# CAN_FD_IP_Core: IP-XACT component
VLNV CTU:ip:CAN_FD_IP_Core:2.1
CAN FD IP Core from Ondrej Ille written at Czech Technical University, department of Measurement.

## Parameters
sup_filt_A = 1
sup_range = 1
sup_filt_C = 1
sup_filt_B = 1
sup_traffic_ctrs = 1
txt_buffer_count = 4
sup_test_registers = 1

## Address spaces and blocks
CAN_Registers.Control_registers: base 'h0, range 256, width 32, register
CAN_Registers.TX_Buffer_1: base 'h100, range 256, width 32, memory
CAN_Registers.TX_Buffer_2: base 'h200, range 256, width 32, memory
CAN_Registers.TX_Buffer_3: base 'h300, range 256, width 32, memory
CAN_Registers.TX_Buffer_4: base 'h400, range 256, width 32, memory
CAN_Registers.TX_Buffer_5: base 'h500, range 256, width 32, memory
CAN_Registers.TX_Buffer_6: base 'h600, range 256, width 32, memory
CAN_Registers.TX_Buffer_7: base 'h700, range 256, width 32, memory
CAN_Registers.TX_Buffer_8: base 'h800, range 256, width 32, memory
CAN_Registers.Test_registers: base 'h900, range 256, width 32, register
CAN_Frame_format.CAN_FD_Frame_format: base 'h0, range 84, width 32

## Registers
Registers are 32-bit, access not given, no defined reset value unless marked. A register's access mark holds for its fields unless they carry their own. Offsets are from the block's base; lines under a group give offsets from that group; [hi:lo] are bit positions; {n}, {i} and the like mark numbered series; 'fields as' and 'values as' point back to an identical list; <NAME> marks a mode.

## CAN_Registers.Control_registers — Control registers memory region.
Base 0x00000000
0x00 DEVICE_ID 16-bit ro reset 0xCAFD — Identifer of CTU CAN FD. Can be used to check if CTU CAN FD is accessible correctly on its base address.
  [15:0] DEVICE_ID
    0xCAFD=CTU_CAN_FD_ID (Identifier of CTU CAN FD.)
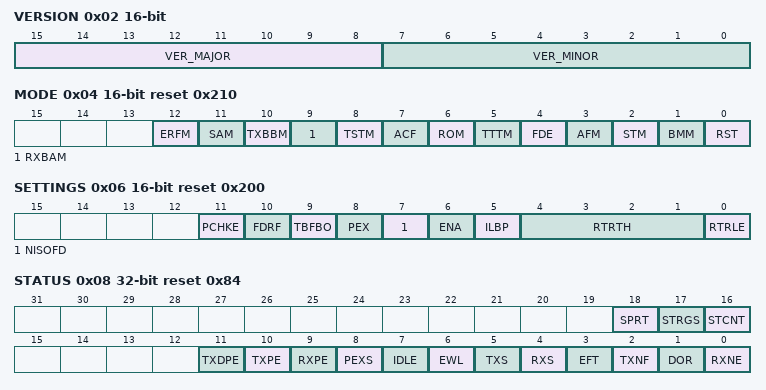
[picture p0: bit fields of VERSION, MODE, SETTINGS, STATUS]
0x02 VERSION 16-bit ro — Version register. Returns version of CTU CAN FD.
  [15:8] VER_MAJOR — Minor part of CTU CAN FD version. E.g for version 2.1 this field has value 0x02.
  [7:0] VER_MINOR — Minor part of CTU CAN FD version. E.g for version 2.1 this field has value 0x01.
0x04 MODE 16-bit rw reset 0x210 (reset mask 0xFFF)
  [12] ERFM — Error Frame Receive mode. When set, CTU CAN FD receives Error frames on CAN bus into its RX buffer.
    1=ERFM_ENABLED (Error frames are stored to RX buffer.); 0=ERFM_DISABLED (Error frames are not stored to RX Buffer.)
  [11] SAM — Self-acknowledge mode.
    0=SAM_DISABLE (Do not send dominant ACK bit when CTU CAN FD sends Acknowledge bit.); 1=SAM_ENABLE (Send dominant ACK bit when CTU CAN FD transmits CAN frame.)
  [10] TXBBM — TXT Buffer Backup mode.
    0=TXBBM_DISABLED (TXT Buffer Backup mode disabled.); 1=TXBBM_ENABLED (TXT Buffer Backup mode enabled.)
  [9] RXBAM — RX Buffer Automatic mode.
    0=RXBAM_DISABLED (RX Buffer Automatic mode Disabled.); 1=RXBAM_ENABLED (RX Buffer Automatic mode Enabled.)
  [8] TSTM — Test Mode. In test mode several registers have special features. Reffer to description of Test mode for further details.
  [7] ACF — Acknowledge Forbidden Mode. When enabled, acknowledge is not sent even if received CRC matches the calculated one.
    1=ACF_ENABLED (Acknowledge forbidden mode enabled.); 0=ACF_DISABLED (Acknowledge forbidden mode disabled.)
  [6] ROM — Restricted operation mode.
    1=ROM_ENABLED (Restricted operation mode is enabled.); 0=ROM_DISABLED (Restricted operation mode is disabled.)
  [5] TTTM — Time triggered transmission mode.
    1=TTTM_ENABLED (Time Triggerer transmission is enabled. A frame from highest priority TXT Buffer in Ready state is admitted for transmission when its timestamp lower than CTU CAN FD timebase.); 0=TTTM_DISABLED (Time Triggerer transmission is disabled. A frame from highest priority TXT Buffer in Ready state is admitted for transmission regardless of its timestamp.)
  [4] FDE — Flexible data rate enable. When flexible data rate is enabled CTU CAN FD recognizes CAN FD frames (FDF bit = 1).
    1=FDE_ENABLE (Flexible data-rate support enabled.); 0=FDE_DISABLE (Flexible data-rate support disabled.)
  [3] AFM — Acceptance Filters Mode. If enabled, only RX frames which pass Frame filters are stored in RX buffer. If disabled, every received frame is stored to RX buffer. This bit has meaning only if there is at least one filter available. Otherwise, this bit is reserved.
    1=AFM_ENABLED (Acceptance filter mode enabled); 0=AFM_DISABLED (Acceptance filter mode disabled)
  [2] STM — Self Test Mode. In this mode transmitted frame is considered valid even if dominant acknowledge was not received.
    1=STM_ENABLED (Self test mode enabled.); 0=STM_DISABLED (Self test mode disabled.)
  [1] BMM — Bus monitoring mode. In this mode CTU CAN FD only receives frames and sends only recessive bits on CAN bus. When a dominant bit is sent, it is re-routed internally so that bus value is not changed. When this mode is enabled, CTU CAN FD will not transmit any frame from TXT Buffers,
    1=BMM_ENABLED (Bus monitoring mode enabled.); 0=BMM_DISABLED (Bus monitoring mode disabled.)
  [0] RST write-clears — Soft reset. Writing logic 1 resets CTU CAN FD. After writing logic 1, logic 0 does not need to be written, this bit is automatically cleared.
0x06 SETTINGS 16-bit rw reset 0x200 (reset mask 0x7FF)
  [11] PCHKE — Enable Parity checks in TXT Buffers and RX Buffer.
  [10] FDRF — Frame filters drop Remote frames.
    1=DROP_RF_ENABLED (Frame filters drop RTR frames.); 0=DROP_RF_DISABLED (Frame filters accept RTR frames.)
  [9] TBFBO — All TXT buffers shall go to "TX failed" state when CTU CAN FD becomes bus-off.
    1=TXTBUF_FAILED_BUS_OFF_ENABLED (TXT Buffers go to "TX failed" state when CTU CAN FD becomes bus-off.); 0=TXTBUF_FAILED_BUS_OFF_DISABLED (TXT Buffers dont go to "TX failed" state when CTU CAN FD becomes bus-off.)
  [8] PEX — Protocol exception handling. When this bit is set, CTU CAN FD will start integration upon detection of protocol exception. This should be modified only when SETTINGS[ENA] = '0'.
    0=PROTOCOL_EXCEPTION_DISABLED (Protocol exception handling is disabled.); 1=PROTOCOL_EXCEPTION_ENABLED (Protocol exception handling is enabled.)
  [7] NISOFD — Non ISO FD. When this bit is set, CTU CAN FD is compliant to NON-ISO CAN FD specification (no stuff count field). This bit should be modified only when SETTINGS[ENA]=0.
    0=ISO_FD (The CAN Controller conforms to ISO CAN FD specification.); 1=NON_ISO_FD (The CAN Controller conforms to NON ISO CAN FD specification.)
  [6] ENA — Main enable bit of CTU CAN FD. When enabled, CTU CAN FD communicates on CAN bus. When disabled, it is bus-off and does not take part of CAN bus communication.
    1=CTU_CAN_ENABLED (The CAN Core is enabled.); 0=CTU_CAN_DISABLED (The CAN Core is disabled.)
  [5] ILBP — Internal Loop Back mode. When enabled, CTU CAN FD receives any frame it transmitts.
    0=INT_LOOP_DISABLED (Internal loop-back is disabled.); 1=INT_LOOP_ENABLED (Internal loop-back is enabled.)
  [4:1] RTRTH — Retransmitt Limit Threshold. Maximal amount of retransmission attempts when SETTINGS[RTRLE] is enabled.
  [0] RTRLE — Retransmitt Limit Enable. If enabled, CTU CAN FD only attempts to retransmitt each frame up to RTR_TH times.
    1=RTRLE_ENABLED (Retransmitt limit is enabled.); 0=RTRLE_DISABLED (Retransmitt limit is disabled.)
0x08 STATUS ro reset 0x84 (reset mask 0xFFF)
  [18] SPRT — Support of Parity protection on each word of TXT Buffer RAM and RX Buffer RAM.
  [17] STRGS — Support of Test Registers for memory testability. When this bit is 1, Test Registers are present.
  [16] STCNT — Support of Traffic counters. When this bit is 1, Traffic counters are present.
  [11] TXDPE — TXT Buffer double parity error. Set in TXT Buffer Backup mode when parity error is detected in "backup" TXT Buffer.
  [10] TXPE — TXT Buffers Parity Error flag. Set When Parity Error is detected in a TXT Buffer during transmission from this buffer.
  [9] RXPE — Set when parity error is detected during read of CAN frame from RX Buffer via RX_DATA register.
  [8] PEXS — Protocol exception status (flag). Set when Protocol exception occurs. Cleared by writing COMMAND[CPEXS]=1.
  [7] IDLE — Bus is idle (no frame is being transmitted/received) or CTU CAN FD is bus-off.
  [6] EWL — TX Error counter (TEC) or RX Error counter (REC) is equal to, or higher than Error warning limit (EWL).
  [5] TXS — CTU CAN FD is transmitter of CAN Frame.
  [4] RXS — CTU CAN FD is receiver of CAN Frame.
  [3] EFT — Error frame is being transmitted at the moment.
  [2] TXNF — TXT buffers status. This bit is set if at least one TXT buffer is in "Empty" state.
  [1] DOR — Data Overrun flag. This bit is set when frame was dropped due to lack of space in RX buffer. This bit can be cleared by COMMAND[RRB] or COMMAND[CDO].
  [0] RXNE — RX buffer not empty. This bit is 1 when least one frame is stored in RX buffer.
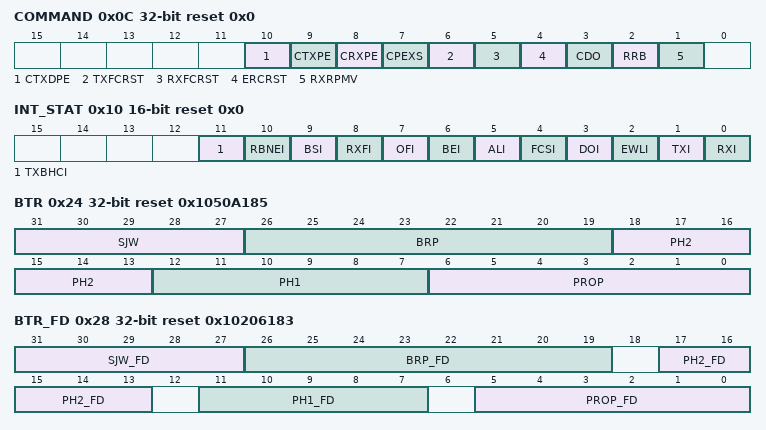
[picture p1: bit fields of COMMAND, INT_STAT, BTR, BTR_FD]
0x0C COMMAND wo reset 0x0 (reset mask 0x7FC) — Allows issuing commands to CTU CAN FD. Writing logic 1 to each bit gives a command to CTU CAN FD. After writing logic 1, logic 0 does not need to be written.
  [10] CTXDPE write-clears — Clear STATUS[TXDPE] flag.
  [9] CTXPE write-clears — Clear STATUS[TXPE] flag.
  [8] CRXPE write-clears — Clear STATUS[RXPE] flag.
  [7] CPEXS write-clears — Clear Protocol exception status (STATUS[PEXS]).
  [6] TXFCRST write-clears — Clear TX bus traffic counter (TX_COUNTER register).
  [5] RXFCRST write-clears — Clear RX bus traffic counter (RX_COUNTER register).
  [4] ERCRST write-clears — Error Counters Reset. When unit is bus off, issuing this command will request erasing TEC, REC counters after 128 consecutive ocurrences of 11 recessive bits. Upon completion, TEC and REC are erased and fault confinement state is set to error-active. When unit is not bus-off, or when unit is bus-off due to being disabled (SETTINGS[ENA] = '0'), this command has no effect.
  [3] CDO write-clears — Clear Data Overrun flag in RX buffer.
  [2] RRB write-clears — Release RX Buffer. This command flushes RX buffer and resets its memory pointers.
  [1] RXRPMV write-clears — RX Buffer read pointer move.
0x10 INT_STAT 16-bit rw-once reset 0x0 — Interrupt Status register. Reading this register returns logic 1 for each interrupt which ocurred. Writing logic 1 to any bit clears according interrupt status. Writing logic 0 has no effect.
  [11] TXBHCI write-clears — TXT buffer HW command interrupt. Anytime TXT buffer receives HW command from CAN Core which changes TXT buffer state to "TX OK", "Error" or "Aborted", this interrupt will be generated.
  [10] RBNEI write-clears — RX buffer not empty interrupt. Clearing this interrupt and not reading out content of RX Buffer via RX_DATA will re-activate the interrupt.
  [9] BSI write-clears — Bit rate shifted interrupt.
  [8] RXFI write-clears — RX buffer full interrupt.
  [7] OFI write-clears — Overload frame interrupt.
  [6] BEI write-clears — Bus error interrupt.
  [5] ALI write-clears — Arbitration lost interrupt.
  [4] FCSI write-clears — Fault confinement state changed interrupt. Interrupt is set when node turns error-passive (from error-active), bus-off (from error-passive) or error-active (from bus-off after reintegration or from error-passive).
  [3] DOI write-clears — Data overrun interrupt. Before this interrupt is cleared , STATUS[DOR] must be cleared to avoid setting of this interrupt again.
  [2] EWLI write-clears — Error warning limit interrupt. When both TEC and REC are lower than EWL and one of the becomes equal to or higher than EWL, or when both TEC and REC become less than EWL, this interrupt is generated. When Interrupt is cleared and REC, or TEC is still equal to or higher than EWL, Interrupt is not generated again.
  [1] TXI write-clears — Frame transmitted interrupt.
  [0] RXI write-clears — Frame received interrupt.
0x14 INT_ENA_SET 16-bit rw-once reset 0x0 — Interrupt Enable Set. Writing logic 1 to a bit enables according interrupt. Writing logic 0 has no effect. Reading this register returns logic 1 for each enabled interrupt. If interrupt is captured in INT_STAT, enabled interrupt will cause CTU CAN FD to raise interrupt. Interrupts are level-based, it remains active until Interrupt status is cleared or interrupt is disabled.
  [11:0] INT_ENA_SET write-clears — Bit meaning is equivalent to register INT_STAT.
0x18 INT_ENA_CLR 16-bit wo reset 0x0 — Interrupt Enable Clear register. Writing logic 1 disables according interrupt. Writing logic 0 has no effect. Reading this register has no effect. Disabled interrupt wil not cause interrupt to be raised by CTU CAN FD even if it is set in Interrupt status register.
  [11:0] INT_ENA_CLR write-clears — Bit meaning is equivalent to register INT_STAT.
0x1C INT_MASK_SET 16-bit rw-once reset 0x0 — Interrupt Mask set. Writing logic 1 masks according interrupt. Writing logic 0 has no effect. Reading this register returns logic 1 for each masked interrupt. If particular interrupt is masked, it won't be captured in INT_STAT register when internal conditions for this interrupt are met (e.g RX buffer is not empty for RXNEI).
  [11:0] INT_MASK_SET write-clears — Bit meaning is equivalent to register INT_STAT.
0x20 INT_MASK_CLR 16-bit wo reset 0x0 — Interrupt Mask clear register. Writing logic 1 un-masks according interrupt. Writing logic 0 has no effect. Reading this register has no effect. If particular interrupt is un-masked, it will be captured in INT_STAT register when internal conditions for this interrupt are met (e.g RX buffer is not empty for RXNEI).
  [11:0] INT_MASK_CLR write-clears — Bit meaning is equivalent to register INT_STAT.
0x24 BTR rw reset 0x1050A185 — Bit timing register for nominal bit rate.
  [31:27] SJW — Synchronisation jump width
  [26:19] BRP — Bit rate prescaler
  [18:13] PH2 — Phase 2 segment
  [12:7] PH1 — Phase 1 segment
  [6:0] PROP — Propagation segment
0x28 BTR_FD rw reset 0x10206183 — Bit timing register for data bit rate.
  [31:27] SJW_FD — Synchronisation jump width
  [26:19] BRP_FD — Bit rate prescaler
  [17:13] PH2_FD — Phase 2 segment
  [11:7] PH1_FD — Phase 1 segment
  [5:0] PROP_FD — Propagation segment
0x2C EWL 8-bit rw reset 0x60 — Error warning limit register. This register shall be modified only when SETTINGS[ENA]=0.
  [7:0] EW_LIMIT — Error warning limit. If error warning limit is reached interrupt can be generated. Error warning limit indicates heavily disturbed bus.
0x2D ERP 8-bit rw reset 0x80 — Error passive limit register. This register shall be modified only when SETTINGS[ENA]=0.
  [7:0] ERP_LIMIT — Error Passive Limit. When one of error counters (REC/TEC) exceeds this value, Fault confinement state changes to error-passive.
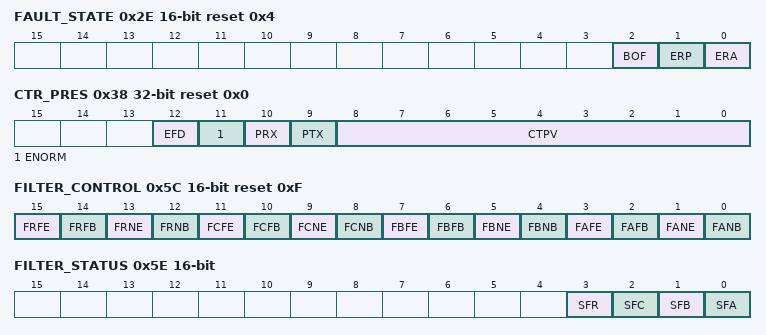
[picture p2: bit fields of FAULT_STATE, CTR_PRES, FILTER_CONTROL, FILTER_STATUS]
0x2E FAULT_STATE 16-bit ro reset 0x4 — Fault Confinement state of the CTU CAN FD.
  [2] BOF — Bus-off
  [1] ERP — Error-passive
  [0] ERA — Error-active
0x30 REC 16-bit ro reset 0x0
  [8:0] REC_VAL — RX error counter (REC).
0x32 TEC 16-bit ro reset 0x0
  [8:0] TEC_VAL — TX error counter (TEC).
0x34 ERR_NORM 16-bit ro reset 0x0
  [15:0] ERR_NORM_VAL — Number of errors which occured in nominal bit rate.
0x36 ERR_FD 16-bit ro reset 0x0
  [15:0] ERR_FD_VAL — Number of errors which occured in data bit rate.
0x38 CTR_PRES wo reset 0x0 — Counter preset register. Error counters can be modified via this register.
  [12] EFD write-clears — Erase Data bit rate error counter (ERR_FD).
  [11] ENORM write-clears — Erase Nominal bit rate error counter (ERR_NORM).
  [10] PRX write-clears — Preset value from CTPV to RX Error counter (REC).
  [9] PTX write-clears — Preset value from CTPV to TX Error counter (TEC).
  [8:0] CTPV — Counter value to set.
0x3C FILTER_A_MASK rw reset 0x0
  [28:0] BIT_MASK_A_VAL — Filter A mask. The identifier format is the same as in IDENTIFIER_W of TXT buffer or RX buffer. If filter A is not present, writes to this register have no effect and read will return all zeroes.
0x40 FILTER_A_VAL rw reset 0x0
  [28:0] BIT_VAL_A_VAL — Filter A value. The identifier format is the same as in IDENTIFIER_W of TXT buffer or RX buffer. If filter A is not present, writes to this register have no effect and read will return all zeroes.
0x44 FILTER_B_MASK rw reset 0x0
  [28:0] BIT_MASK_B_VAL — Filter B mask. The identifier format is the same as in IDENTIFIER_W of TXT buffer or RX buffer. If filter A is not present, writes to this register have no effect and read will return all zeroes.
0x48 FILTER_B_VAL rw reset 0x0
  [28:0] BIT_VAL_B_VAL — Filter B value. The identifier format is the same as in IDENTIFIER_W of TXT buffer or RX buffer. If filter A is not present, writes to this register have no effect and read will return all zeroes.
0x4C FILTER_C_MASK rw reset 0x0
  [28:0] BIT_MASK_C_VAL — Filter C mask. The identifier format is the same as in IDENTIFIER_W of TXT buffer or RX buffer. If filter A is not present, writes to this register have no effect and read will return all zeroes.
0x50 FILTER_C_VAL rw reset 0x0
  [28:0] BIT_VAL_C_VAL — Filter C value. The identifier format is the same as in IDENTIFIER_W of TXT buffer or RX buffer. If filter A is not present, writes to this register have no effect and read will return all zeroes.
0x54 FILTER_RAN_LOW rw reset 0x0
  [28:0] BIT_RAN_LOW_VAL — Filter Range Low threshold. The identifier format is the same as in IDENTIFIER_W of TXT buffer or RX buffer. If Range filter is not supported, writes to this register have no effect and read will return all zeroes.
0x58 FILTER_RAN_HIGH rw reset 0x0
  [28:0] BIT_RAN_HIGH_VAL — Range filter High threshold. The identifier format is the same as in IDENTIFIER_W of TXT buffer or RX buffer. If Range filter is not supported, writes to this register have no effect and read will return all zeroes.
0x5C FILTER_CONTROL 16-bit rw reset 0xF — Filter control register. Configures Frame filters to accept only selected frame types. Every bit is active in logic 1.
  [15] FRFE — CAN FD Extended Frame is accepted by Range filter.
  [14] FRFB — CAN FD Basic Frame is accepted by Range filter.
  [13] FRNE — CAN Extended Frame is accepted by Range filter.
  [12] FRNB — CAN Basic Frame is accepted by Range filter.
  [11] FCFE — CAN FD Extended Frame is accepted by filter C.
  [10] FCFB — CAN FD Basic Frame is accepted by filter C.
  [9] FCNE — CAN Extended Frame is accepted by Filter C.
  [8] FCNB — CAN Basic Frame is accepted by filter C.
  [7] FBFE — CAN FD Extended Frame is accepted by filter B.
  [6] FBFB — CAN FD Basic Frame is accepted by filter B.
  [5] FBNE — CAN Extended Frame is accepted by Filter B.
  [4] FBNB — CAN Basic Frame is accepted by filter B.
  [3] FAFE — CAN FD Extended Frame is accepted by filter A.
  [2] FAFB — CAN FD Basic Frame is accepted by filter A.
  [1] FANE — CAN Extended Frame is accepted by Filter A.
  [0] FANB — CAN Basic Frame is accepted by filter A.
0x5E FILTER_STATUS 16-bit ro — Filter status indicates if frame filters are available in CTU CAN FD.
  [3] SFR — Logic 1 when Range Filter is available. Otherwise logic 0.
  [2] SFC — Logic 1 when Filter C is available. Otherwise logic 0.
  [1] SFB — Logic 1 when Filter B is available. Otherwise logic 0.
  [0] SFA — Logic 1 when Filter A is available. Otherwise logic 0.
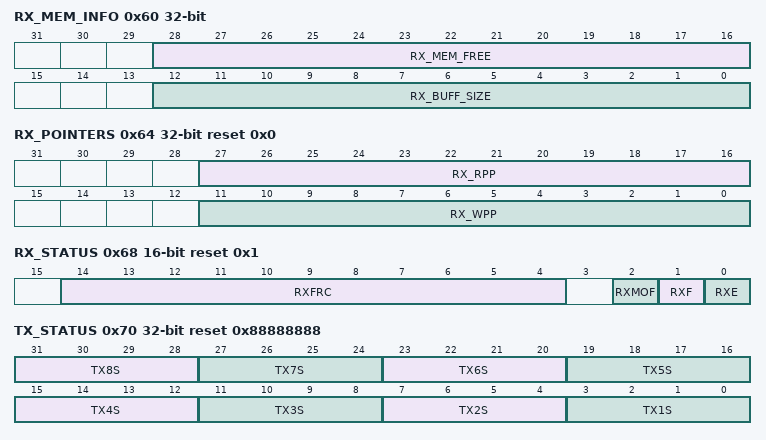
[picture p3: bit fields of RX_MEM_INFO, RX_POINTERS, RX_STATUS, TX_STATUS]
0x60 RX_MEM_INFO ro
  [28:16] RX_MEM_FREE — Number of free 32 bit words in RX buffer.
  [12:0] RX_BUFF_SIZE — Size of RX buffer in 32-bit words.
0x64 RX_POINTERS ro reset 0x0
  [27:16] RX_RPP — Read pointer position in RX buffer. Upon read of received frame read pointer is updated.
  [11:0] RX_WPP — Write pointer position in RX buffer. Upon store of received frame write pointer is updated.
0x68 RX_STATUS 16-bit ro reset 0x1
  [14:4] RXFRC — RX buffer frame count. Number of CAN frames stored in RX buffer.
  [2] RXMOF — RX Buffer middle of frame. When RXMOF = 1, next read from RX_DATA register will return other than first word (FRAME_FORMAT_W) of CAN frame.
  [1] RXF — RX buffer is full, all memory words of RX buffer are occupied.
  [0] RXE — RX buffer is empty. There is no CAN Frame stored in it.
0x6A RX_SETTINGS 8-bit rw reset 0x0 — Settings of RX buffer FIFO.
  [0] RTSOP — Receive buffer timestamp option. This register should be modified only when SETTINGS[ENA]=0.
    0=RTS_END (Timestamp of received frame in RX FIFO is captured in last bit of EOF field.); 1=RTS_BEG (Timestamp of received frame in RX FIFO is captured in SOF field.)
0x6C RX_DATA ro reset 0x0
  [31:0] RX_DATA read-modifies — RX buffer data at read pointer position in FIFO. By reading from this register, read pointer is automatically incremented if MODES[RXBAM]=1 and RX Buffer is not empty. If MODE[RXBAM]=1, this register must be read by 32 bit access. Upon read from this register, STATUS[RXPE] is set if there is parity error detected in RX Buffer word which is being read.
0x70 TX_STATUS ro reset 0x88888888
  [4n-1:4n-4] TX{n}S (n=2..8) — Status of TXT buffer {n}. Bit field meaning is analogous to TX1S.
  [3:0] TX1S — Status of TXT buffer 1.
    8=TXT_ETY (TXT buffer is in "Empty" state.); 4=TXT_TOK (TXT buffer is in "TX OK" state.); 6=TXT_ERR (TXT buffer is in "Failed" state.); 0=TXT_NOT_EXIST (TXT buffer does not exist in the core (applies only to TXT buffers 3-8, when CTU CAN FD was synthesized with less than 8 TXT buffers).); 9=TXT_PER (TXT Buffer is in "Parity Error" state. CTU CAN FD detected parity error on this buffer.); 7=TXT_ABT (TXT buffer is in "Aborted" state.); 2=TXT_TRAN (TXT buffer is in "TX in progress" state. CTU CAN FD is transmitting frame.); 3=TXT_ABTP (TXT buffer is in "Abort in progress" state.); 1=TXT_RDY (TXT buffer is in "Ready" state, it is waiting for CTU CAN FD to start transmission from it.)
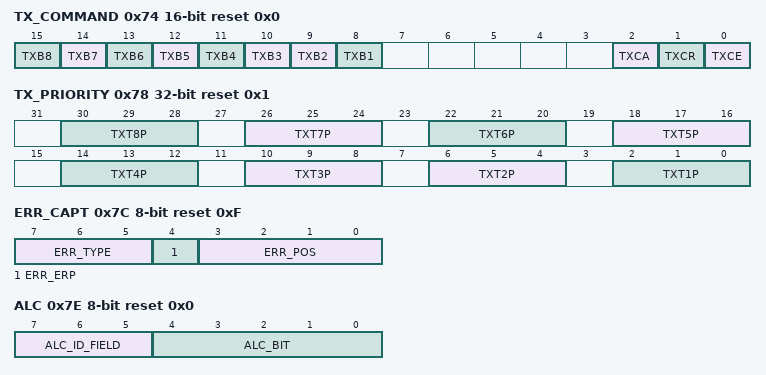
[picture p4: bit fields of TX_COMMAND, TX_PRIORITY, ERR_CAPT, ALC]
0x74 TX_COMMAND 16-bit wo reset 0x0 — Command register for TXT buffers. Command is activated by writing logic 1 to TXC(E|R|A) bit. TXT buffer that receives the command is selected by setting bit TXB[1-8] to logic 1. Command and index can be set by single access, or index can be set in advance. TXC(E|R|A) bits are automatically erased upon the command completion. Reffer to description of TXT buffer for meaning of commands. If TXCE and TXCR are applied simultaneously, only TXCE command is applied. If multiple commands are applied at once, only those which have effect in immediate state of TXT buffer are applied to the buffer.
  [n+7] TXB{n} (n=3..8) — Command is issued to TXT Buffer {n}. If number of TXT Buffers is less than {n}, this field is reserved and has no function.
  [9] TXB2 — Command is issued to TXT Buffer 2.
  [8] TXB1 — Command is issued to TXT Buffer 1.
  [2] TXCA write-clears — Issues "set abort" command.
  [1] TXCR write-clears — Issues "set ready" command.
  [0] TXCE write-clears — Issues "set empty" command.
0x76 TXTB_INFO 16-bit ro — Register with information about supported features of TXT buffers.
  [3:0] TXT_BUFFER_COUNT — Number of TXT buffers present in CTU CAN FD. Lowest buffer is always 1. Highest buffer is at index equal to number of present buffers.
0x78 TX_PRIORITY rw reset 0x1 — Priority of TXT buffers. Highest priority TXT buffer in "Ready" state is selected for transmission.
  [4n-2:4n-4] TXT{n}P (n=3..8) — Priority of TXT buffer {n}. If number of TXT Buffers is less than {n}, this field is reserved and has no function.
  [6:4] TXT2P — Priority of TXT buffer 2.
  [2:0] TXT1P — Priority of TXT buffer 1.
0x7C ERR_CAPT 8-bit ro reset 0xF — Error code capture register. Determines position within CAN frame where last error was detected.
  [7:5] ERR_TYPE — Type of last error.
    0=ERC_BIT_ERR (Bit Error); 1=ERC_CRC_ERR (CRC Error); 2=ERC_FRM_ERR (Form Error); 3=ERC_ACK_ERR (Acknowledge Error); 4=ERC_STUF_ERR (Stuff Error); 5=ERC_PRT_ERR (Parity Error in TXT Buffer RAM DATA_1_4_W ... DATA_61_64_W words.)
  [4] ERR_ERP — CTU CAN FD was error passive the time when last error was detected.
    1=ERR_ERP_PASSIVE (CTU CAN FD was error active when it detected the error condition.); 0=ERR_ERP_ACTIVE (CTU CAN FD was error passive when it detected the error condition.)
  [3:0] ERR_POS — Position of last error.
    0=ERC_POS_SOF (Error in Start of Frame); 1=ERC_POS_ARB (Error in Arbitration Filed); 7=ERC_POS_ERR (Error during Error frame); 8=ERC_POS_OVRL (Error in Overload frame); 2=ERC_POS_CTRL (Error in Control field); 15=ERC_POS_OTHER (Other position of error); 3=ERC_POS_DATA (Error in Data Field); 4=ERC_POS_CRC (Error in CRC Field); 6=ERC_POS_EOF (Error in End of frame field); 5=ERC_POS_ACK (Error in CRC delimiter, ACK field or ACK delimiter)
0x7D RETR_CTR 8-bit ro reset 0x0 — Current value of Retransmit counter.
  [3:0] RETR_CTR_VAL — Current value of retransmitt counter.
0x7E ALC 8-bit ro reset 0x0 — Arbitration lost capture register. Determines position of last arbitration loss within CAN frame.
  [7:5] ALC_ID_FIELD — Part of CAN Identifier in which arbitration was lost.
    1=ALC_BASE_ID (Arbitration was lost during base identifier.); 2=ALC_SRR_RTR (Arbitration was lost during first bit after base identifier (SRR of Extended Frame, RTR bit of CAN 2.0 Base Frame)); 3=ALC_IDE (Arbitration was lost during IDE bit.); 4=ALC_EXTENSION (Arbitration was lost during Identifier extension.); 5=ALC_RTR (Arbitration was lost during RTR bit after Identifier extension!); 0=ALC_RSVD (Unit did not loose arbitration since last reset.)
  [4:0] ALC_BIT — Arbitration lost capture bit position. If ALC_ID_FIELD = ALC_BASE_ID then bit index of BASE identifier in which arbitration was lost is given as: 11 - ALC_VAL. If ALC_ID_FIELD = ALC_EXTENSION then bit index of EXTENDED identifier in which arbitration was lost is given as: 18 - ALC_VAL. For other values of ALC_ID_FIELD, this value is undefined.
0x7F TS_INFO 8-bit ro — Timestamp integration information
  [5:0] TS_BITS — Number of active bits of CTU CAN FD time-base minus 1 (0x3F = 64 bit time-base).
0x80 TRV_DELAY 16-bit ro reset 0x0 — Transmitter delay register. When transmitting CAN FD Frame, Transmitter delay is measured. After the measurement (after FDF bit), it can be read out from this register. The value in this register is valid since first transmission of CAN FD frame. After each next measurement the value is updated.
  [7:0] TRV_DELAY_VALUE — Measured Transmitter delay in multiple of minimal Time quanta.
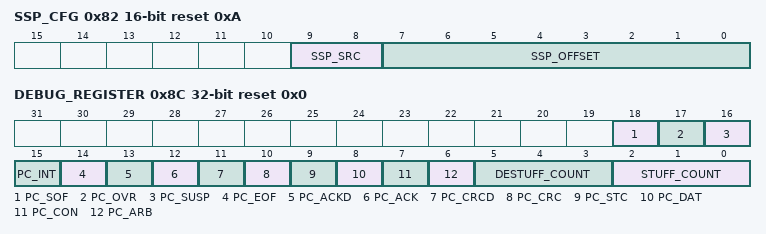
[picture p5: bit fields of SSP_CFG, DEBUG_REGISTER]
0x82 SSP_CFG 16-bit rw reset 0xA — Secondary sampling point configuration register. Used by transmitter in data bit rate for calculation of Secondary sampling point.
  [9:8] SSP_SRC — Source of Secondary sampling point.
    2=SSP_SRC_OFFSET (SSP position = SSP_OFFSET. Measured Transmitter delay value is ignored.); 0=SSP_SRC_MEAS_N_OFFSET (SSP position = TRV_DELAY (Measured Transmitter delay) + SSP_OFFSET.); 1=SSP_SRC_NO_SSP (SSP is not used. Transmitter uses regular Sampling Point during data bit rate.)
  [7:0] SSP_OFFSET — Secondary sampling point offset. Value is given as multiple of minimal Time quanta.
0x84 RX_FR_CTR ro reset 0x0
  [31:0] RX_FR_CTR_VAL — Number of received frames by CTU CAN FD.
0x88 TX_FR_CTR ro reset 0x0
  [31:0] TX_FR_CTR_VAL — Number of transmitted frames by CTU CAN FD.
0x8C DEBUG_REGISTER ro reset 0x0 — Register for reading state of the controller. This register is only for debugging purposes!
  [18] PC_SOF — Protocol control state machine is in Start of frame field.
  [17] PC_OVR — Protocol control state machine is in Overload field.
  [16] PC_SUSP — Protocol control state machine is in Suspend transmission field.
  [15] PC_INT — Protocol control state machine is in Intermission field.
  [14] PC_EOF — Protocol control state machine is in End of file field.
  [13] PC_ACKD — Protocol control state machine is in ACK Delimiter field.
  [12] PC_ACK — Protocol control state machine is in ACK field.
  [11] PC_CRCD — Protocol control state machine is in CRC Delimiter field.
  [10] PC_CRC — Protocol control state machine is in CRC field.
  [9] PC_STC — Protocol control state machine is in Stuff Count field.
  [8] PC_DAT — Protocol control state machine is in Data field.
  [7] PC_CON — Protocol control state machine is in Control field.
  [6] PC_ARB — Protocol control state machine is in Arbitration field.
  [5:3] DESTUFF_COUNT — Actual de-stuff count modulo 8 as defined in ISO FD protocol. De-Stuff count is erased in the beginning of the frame and increased by one with each de-stuffed bit until Stuff count field in ISO FD Frame. Then it stays fixed until beginning of next frame. In non-ISO FD or normal CAN de-stuff bits are counted until the end of the frame. Note that this field is NOT grey encoded as defined in ISO FD standard. De-stuff count is calculated in both. Transceiver as well as receiver.
  [2:0] STUFF_COUNT — Actual stuff count modulo 8 as definned in ISO FD protocol. Stuff count is erased in the beginning of CAN frame and increased by one with each stuff bit until Stuff count field in ISO FD frame. Then it stays fixed until the beginning of next frame. In non-ISO FD or normal CAN stuff bits are counted until the end of a frame. Note that this field is NOT gray encoded as defined in ISO FD standard. Stuff count is calculated only as long as controller is transceiving on the bus. During the reception this value remains fixed!
0x90 YOLO_REG ro reset 0xDEADBEEF — Register for fun :)
  [31:0] YOLO_VAL — What else could be in this register??
0x94 TIMESTAMP_LOW ro — Register with current value of CTU CAN FD time base. No shadowing is implemented on TIMESTAMP_LOW/HIGH registers and user has to take care of proper read from both registers, since overflow of TIMESTAMP_LOW might occur between read of TIMESTAMP_LOW and TIMESTAMP_HIGH.
  [31:0] TIMESTAMP_LOW — Bits 31:0 of time base.
0x98 TIMESTAMP_HIGH ro — Register with current value of CTU CAN FD time base. No shadowing is implemented on TIMESTAMP_LOW/HIGH registers and user has to take care of proper read from both registers, since overflow of TIMESTAMP_LOW might occur between read of TIMESTAMP_LOW and TIMESTAMP_HIGH.
  [31:0] TIMESTAMP_HIGH — Bits 63:32 of time base.

## CAN_Registers.TX_Buffer_1 — Access to this memory region is mapped to TXT buffer 1. CAN FD frame for transmittion can be inserted to this buffer. The frame layout corresponds to the layout described in Chapter "CAN FD frame format". First adress in this region (TXTB1_DATA_1) corresponds to FRAME_FORMAT_W, second address (TXTB1_DATA_2) corresponds to IDENTIFIER_W etc. The last address (TXTB1_DATA_20) corresponds to DATA_61_64_W. The adresses in between correspond linearly. This memory region is write only and read access will return all zeroes. This region is write only.
Base 0x00000100
0x00 TXTB1_DATA_1 — This adress word corresponds to FRAME_FORM word
0x04 TXTB1_DATA_2 — This adress word corresponds to IDENTIFIER word.
0x08 TXTB1_DATA_3
0x0C TXTB1_DATA_4
0x10 TXTB1_DATA_5
0x14 TXTB1_DATA_6
0x18 TXTB1_DATA_7
0x1C TXTB1_DATA_8
0x20 TXTB1_DATA_9
0x24 TXTB1_DATA_10
0x28 TXTB1_DATA_11
0x2C TXTB1_DATA_12
0x30 TXTB1_DATA_13
0x34 TXTB1_DATA_14
0x38 TXTB1_DATA_15
0x3C TXTB1_DATA_16
0x40 TXTB1_DATA_17
0x44 TXTB1_DATA_18
0x48 TXTB1_DATA_19
0x4C TXTB1_DATA_20 — This adress word corresponds to DATA_61_64 word.
0x50 TXTB1_DATA_21

## CAN_Registers.TX_Buffer_2 — Access to this memory region is mapped to TXT buffer 2. CAN FD frame for transmittion can be inserted to this buffer. The frame layout corresponds to the layout described in Chapter "CAN FD frame format". First adress in this region (TXTB2_DATA_1) corresponds to FRAME_FORMAT_W, second address (TXTB2_DATA_2) corresponds to IDENTIFIER_W etc. The last address (TXTB2_DATA_20) corresponds to DATA_61_64_W. The adresses in between correspond linearly. This memory region is write only and read access will return all zeroes. This region is write only.
Base 0x00000200
0x00 TXTB2_DATA_1 — This adress word corresponds to FRAME_FORM word
0x04 TXTB2_DATA_2 — This adress word corresponds to IDENTIFIER word.
0x08 TXTB2_DATA_3
0x0C TXTB2_DATA_4
0x10 TXTB2_DATA_5
0x14 TXTB2_DATA_6
0x18 TXTB2_DATA_7
0x1C TXTB2_DATA_8
0x20 TXTB2_DATA_9
0x24 TXTB2_DATA_10
0x28 TXTB2_DATA_11
0x2C TXTB2_DATA_12
0x30 TXTB2_DATA_13
0x34 TXTB2_DATA_14
0x38 TXTB2_DATA_15
0x3C TXTB2_DATA_16
0x40 TXTB2_DATA_17
0x44 TXTB2_DATA_18
0x48 TXTB2_DATA_19
0x4C TXTB2_DATA_20 — This adress word corresponds to DATA_61_64 word.
0x50 TXTB2_DATA_21

## CAN_Registers.TX_Buffer_3 — Access to this memory region is mapped to TXT buffer 3. CAN FD frame for transmittion can be inserted to this buffer. The frame layout corresponds to the layout described in Chapter "CAN FD frame format". First adress in this region (TXTB3_DATA_1) corresponds to FRAME_FORMAT_W, second address (TXTB3_DATA_2) corresponds to IDENTIFIER_W etc. The last address (TXTB3_DATA_20) corresponds to DATA_61_64_W. The adresses in between correspond linearly. This memory region is write only and read access will return all zeroes. This region is write only.
Base 0x00000300
0x00 TXTB3_DATA_1 — This adress word corresponds to FRAME_FORM word
0x04 TXTB3_DATA_2 — This adress word corresponds to IDENTIFIER word.
0x08 TXTB3_DATA_3
0x0C TXTB3_DATA_4
0x10 TXTB3_DATA_5
0x14 TXTB3_DATA_6
0x18 TXTB3_DATA_7
0x1C TXTB3_DATA_8
0x20 TXTB3_DATA_9
0x24 TXTB3_DATA_10
0x28 TXTB3_DATA_11
0x2C TXTB3_DATA_12
0x30 TXTB3_DATA_13
0x34 TXTB3_DATA_14
0x38 TXTB3_DATA_15
0x3C TXTB3_DATA_16
0x40 TXTB3_DATA_17
0x44 TXTB3_DATA_18
0x48 TXTB3_DATA_19
0x4C TXTB3_DATA_20 — This adress word corresponds to DATA_61_64 word.
0x50 TXTB3_DATA_21

## CAN_Registers.TX_Buffer_4 — Access to this memory region is mapped to TXT buffer 4. CAN FD frame for transmittion can be inserted to this buffer. The frame layout corresponds to the layout described in Chapter "CAN FD frame format". First adress in this region (TXTB4_DATA_1) corresponds to FRAME_FORMAT_W, second address (TXTB4_DATA_2) corresponds to IDENTIFIER_W etc. The last address (TXTB4_DATA_20) corresponds to DATA_61_64_W. The adresses in between correspond linearly. This memory region is write only and read access will return all zeroes. This region is write only.
Base 0x00000400
0x00 TXTB4_DATA_1 — This adress word corresponds to FRAME_FORM word
0x04 TXTB4_DATA_2 — This adress word corresponds to IDENTIFIER word.
0x08 TXTB4_DATA_3
0x0C TXTB4_DATA_4
0x10 TXTB4_DATA_5
0x14 TXTB4_DATA_6
0x18 TXTB4_DATA_7
0x1C TXTB4_DATA_8
0x20 TXTB4_DATA_9
0x24 TXTB4_DATA_10
0x28 TXTB4_DATA_11
0x2C TXTB4_DATA_12
0x30 TXTB4_DATA_13
0x34 TXTB4_DATA_14
0x38 TXTB4_DATA_15
0x3C TXTB4_DATA_16
0x40 TXTB4_DATA_17
0x44 TXTB4_DATA_18
0x48 TXTB4_DATA_19
0x4C TXTB4_DATA_20 — This adress word corresponds to DATA_61_64 word.
0x50 TXTB4_DATA_21

## CAN_Registers.TX_Buffer_5 — Access to this memory region is mapped to TXT buffer 5. CAN FD frame for transmittion can be inserted to this buffer. The frame layout corresponds to the layout described in Chapter "CAN FD frame format". First adress in this region (TXTB5_DATA_1) corresponds to FRAME_FORMAT_W, second address (TXTB5_DATA_2) corresponds to IDENTIFIER_W etc. The last address (TXTB5_DATA_20) corresponds to DATA_61_64_W. The adresses in between correspond linearly. This memory region is write only and read access will return all zeroes. This region is write only.
Base 0x00000500
0x00 TXTB5_DATA_1 — This adress word corresponds to FRAME_FORM word
0x04 TXTB5_DATA_2 — This adress word corresponds to IDENTIFIER word.
0x08 TXTB5_DATA_3
0x0C TXTB5_DATA_4
0x10 TXTB5_DATA_5
0x14 TXTB5_DATA_6
0x18 TXTB5_DATA_7
0x1C TXTB5_DATA_8
0x20 TXTB5_DATA_9
0x24 TXTB5_DATA_10
0x28 TXTB5_DATA_11
0x2C TXTB5_DATA_12
0x30 TXTB5_DATA_13
0x34 TXTB5_DATA_14
0x38 TXTB5_DATA_15
0x3C TXTB5_DATA_16 — This adress word corresponds to DATA_61_64 word.
0x40 TXTB5_DATA_17
0x44 TXTB5_DATA_18
0x48 TXTB5_DATA_19
0x4C TXTB5_DATA_20
0x50 TXTB5_DATA_21

## CAN_Registers.TX_Buffer_6 — Access to this memory region is mapped to TXT buffer 6. CAN FD frame for transmittion can be inserted to this buffer. The frame layout corresponds to the layout described in Chapter "CAN FD frame format". First adress in this region (TXTB6_DATA_1) corresponds to FRAME_FORMAT_W, second address (TXTB6_DATA_2) corresponds to IDENTIFIER_W etc. The last address (TXTB6_DATA_20) corresponds to DATA_61_64_W. The adresses in between correspond linearly. This memory region is write only and read access will return all zeroes. This region is write only.
Base 0x00000600
0x00 TXTB6_DATA_1 — This adress word corresponds to FRAME_FORM word
0x04 TXTB6_DATA_2 — This adress word corresponds to IDENTIFIER word.
0x08 TXTB6_DATA_3
0x0C TXTB6_DATA_4
0x10 TXTB6_DATA_5
0x14 TXTB6_DATA_6
0x18 TXTB6_DATA_7
0x1C TXTB6_DATA_8
0x20 TXTB6_DATA_9
0x24 TXTB6_DATA_10
0x28 TXTB6_DATA_11
0x2C TXTB6_DATA_12
0x30 TXTB6_DATA_13
0x34 TXTB6_DATA_14
0x38 TXTB6_DATA_15
0x3C TXTB6_DATA_16
0x40 TXTB6_DATA_17
0x44 TXTB6_DATA_18
0x48 TXTB6_DATA_19
0x4C TXTB6_DATA_20 — This adress word corresponds to DATA_61_64 word.
0x50 TXTB6_DATA_21

## CAN_Registers.TX_Buffer_7 — Access to this memory region is mapped to TXT buffer 7. CAN FD frame for transmittion can be inserted to this buffer. The frame layout corresponds to the layout described in Chapter "CAN FD frame format". First adress in this region (TXTB7_DATA_1) corresponds to FRAME_FORMAT_W, second address (TXTB7_DATA_2) corresponds to IDENTIFIER_W etc. The last address (TXTB7_DATA_20) corresponds to DATA_61_64_W. The adresses in between correspond linearly. This memory region is write only and read access will return all zeroes. This region is write only.
Base 0x00000700
0x00 TXTB7_DATA_1 — This adress word corresponds to FRAME_FORM word
0x04 TXTB7_DATA_2 — This adress word corresponds to IDENTIFIER word.
0x08 TXTB7_DATA_3
0x0C TXTB7_DATA_4
0x10 TXTB7_DATA_5
0x14 TXTB7_DATA_6
0x18 TXTB7_DATA_7
0x1C TXTB7_DATA_8
0x20 TXTB7_DATA_9
0x24 TXTB7_DATA_10
0x28 TXTB7_DATA_11
0x2C TXTB7_DATA_12
0x30 TXTB7_DATA_13
0x34 TXTB7_DATA_14
0x38 TXTB7_DATA_15
0x3C TXTB7_DATA_16
0x40 TXTB7_DATA_17
0x44 TXTB7_DATA_18
0x48 TXTB7_DATA_19
0x4C TXTB7_DATA_20 — This adress word corresponds to DATA_61_64 word.
0x50 TXTB7_DATA_21

## CAN_Registers.TX_Buffer_8 — Access to this memory region is mapped to TXT buffer 8. CAN FD frame for transmittion can be inserted to this buffer. The frame layout corresponds to the layout described in Chapter "CAN FD frame format". First adress in this region (TXTB8_DATA_1) corresponds to FRAME_FORMAT_W, second address (TXTB8_DATA_2) corresponds to IDENTIFIER_W etc. The last address (TXTB8_DATA_20) corresponds to DATA_61_64_W. The adresses in between correspond linearly. This memory region is write only and read access will return all zeroes. This region is write only.
Base 0x00000800
0x00 TXTB8_DATA_1 — This adress word corresponds to FRAME_FORM word
0x04 TXTB8_DATA_2 — This adress word corresponds to IDENTIFIER word.
0x08 TXTB8_DATA_3
0x0C TXTB8_DATA_4
0x10 TXTB8_DATA_5
0x14 TXTB8_DATA_6
0x18 TXTB8_DATA_7
0x1C TXTB8_DATA_8
0x20 TXTB8_DATA_9
0x24 TXTB8_DATA_10
0x28 TXTB8_DATA_11
0x2C TXTB8_DATA_12
0x30 TXTB8_DATA_13
0x34 TXTB8_DATA_14
0x38 TXTB8_DATA_15
0x3C TXTB8_DATA_16 — This adress word corresponds to DATA_61_64 word.
0x40 TXTB8_DATA_17
0x44 TXTB8_DATA_18
0x48 TXTB8_DATA_19
0x4C TXTB8_DATA_20
0x50 TXTB8_DATA_21

## CAN_Registers.Test_registers — Test registers memory region. Contains registers with manufacturing testability features.
Base 0x00000900
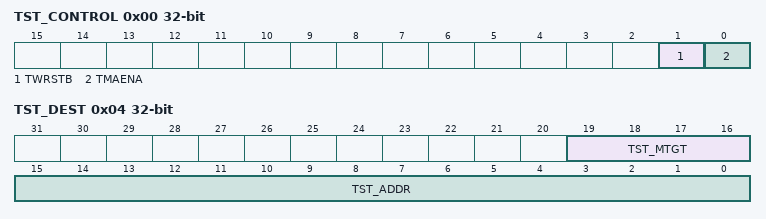
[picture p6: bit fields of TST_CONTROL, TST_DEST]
0x00 TST_CONTROL rw — Testability control register. Contains configuration of test functions.
  [1] TWRSTB write-clears — Writing 1 executes write acess to a memory/address given by TST_DEST register. 0 does not need to be written, this bit is cleared automatically.
  [0] TMAENA — Enable test access to CTU CAN FD memories.
0x04 TST_DEST rw
  [19:16] TST_MTGT — Target memory to be accessed.
    {v}=TMTGT_TXTBUF{v-1} (TXT buffer {v-1} memory is selected for test access.) (v=2..9); 1=TMTGT_RXBUF (RX buffer memory is selected for test access.); 0=TMTGT_NONE (No target memory is selected for test access.)
  [15:0] TST_ADDR — Address for test memory access within tested memory.
0x08 TST_WDATA rw
  [31:0] TST_WDATA — Write data for test access.
0x0C TST_RDATA ro
  [31:0] TST_RDATA — Read data for test access.

## CAN_Frame_format.CAN_FD_Frame_format
Base 0x00000000
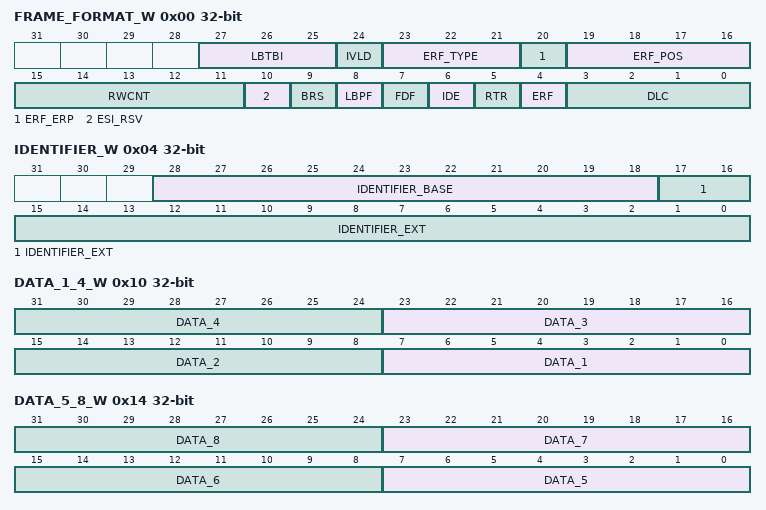
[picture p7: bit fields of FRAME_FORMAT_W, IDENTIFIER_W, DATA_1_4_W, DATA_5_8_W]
0x00 FRAME_FORMAT_W — Frame format word with CAN frame metadata.
  [27:25] LBTBI — Loop-Back TXT Buffer index. This field is only valid in RX Buffer and when FRAME_FORMAT_W[LBTBI]=1. This field has no meaning in TXT Buffers.
    {v}=TXT_BUF_{v+1} (TXT Buffer {v+1}) (v=0..7)
  [24] IVLD — IDENTIFIER_W word contains a valid identifier. This field is valid only in RX Buffer, it has no meaning in TXT Buffers.
    1=IVLD_VALID (IDENTIFIER_W contains a valid CAN FD identifier.); 0=IVLD_INALID (IDENTIFIER_W does not contain a valid CAN FD identifier.)
  [23:21] ERF_TYPE — Error frame type of Error Frame recorder in RX Buffer. This bit has no meaning in TXT Buffers. The encoding of this field is equal to ERR_CAPT[ERR_TYPE] register.
  [20] ERF_ERP — CTU CAN FD was Error Passive state at time when the error was detected and stored to the RX Buffer. This bit has no meaning in TXT Buffers. The encoding of this field is equal to ERR_CAPT[ERR_STATE] register.
  [19:16] ERF_POS — Error Frame position of Error Frame recorder in RX Buffer. This bit has no meaning in TXT Buffers. The encoding of this field is equal to ERR_CAPT[ERR_POS] register.
  [15:11] RWCNT — Size of CAN frame in RX buffer without FRAME_FORMAT WORD. (E.g RTR frame RWCNT=3, 64 Byte FD frame RWCNT=19). In TXT buffer this field has no meaning.
  [10] ESI_RSV — Error State Indicator bit for received CAN FD frames. Bit has no meaning for CAN frames nor for transmitted CAN FD frames (in TXT buffer).
    0=ESI_ERR_ACTIVE (Transmitted of received CAN FD frame is error active.); 1=ESI_ERR_PASIVE (Transmitted of received CAN FD frame is error passive.)
  [9] BRS — Bit Rate Shift. In case of CAN FD frames indicates whether bit rate is shifted CAN FD frame. This bit has no meaning for CAN frames.
    1=BR_SHIFT (Bit rate should be shifted if frame is CAN FD frame.); 0=BR_NO_SHIFT (Bit rate should not be shifted if frame is CAN FD frame.)
  [8] LBPF — Loop-Back Frame. When this bit is set, the current frame in RX Buffer was a frame transmitted by unit itself due to operation in Loopback Mode. This bit has no meaning in TXT Buffers.
    1=LBPF_LOOPBACK (The frame was transmitted by the unit itself.); 0=LBPF_FOREIGN (The frame was transmitted by other node on the bus.)
  [7] FDF — Flexible Data-rate Format. Distinguishes between CAN 2.0 and CAN FD Frames.
    0=NORMAL_CAN (Frame is CAN frame.); 1=FD_CAN (Frame is CAN FD frame.)
  [6] IDE — Extended Identifier Type. Logic 1 indicates CAN frame with both Base identifier and Identifier extension. Logic 0 indicates CAN frame with only Base identifier.
    0=BASE (Frame Identifier is Basic (11 bits)); 1=EXTENDED (Frame Identifier is Extended (11 + 18 bits))
  [5] RTR — Logic 1 indicates Remote frame. Has meaning only for CAN frames. CAN FD does not have RTR frames.
    1=RTR_FRAME (CAN frame is RTR frame.); 0=NO_RTR_FRAME (CAN frame is not RTR frame.)
  [4] ERF — Error Frame Flag. When set, the current frame in RX Buffer is an Error frame. This bit has no meaning in TXT buffers.
    0=ERF_CAN_FRAME (Frame in RX Buffer is an Error frame.); 1=ERF_ERR_FRAME (Frame in RX Buffer is a regular CAN frame)
  [3:0] DLC — Data Length Code.
0x04 IDENTIFIER_W — CAN Identifier.
  [28:18] IDENTIFIER_BASE — Base Identifier of CAN frame.
  [17:0] IDENTIFIER_EXT — Extended Identifier of CAN frame. Has meaning only if IDE of FRAME_FORMAT_W is EXTENDED.
0x08 TIMESTAMP_L_W
  [31:0] TIME_STAMP_L_W — Lower 32 bits of timestamp when the frame should be transmitted or when it was received.
0x0C TIMESTAMP_U_W
  [31:0] TIMESTAMP_U_W — Upper 32 bits of timestamp when the frame should be transmitted or when it was received.
0x10 DATA_1_4_W
  [8n-1:8n-8] DATA_{n} (n=1..4) — Data byte {n} of CAN Frame.
0x14 DATA_5_8_W
  [8n-33:8n-40] DATA_{n} (n=5..8) — Data byte {n} of CAN Frame.
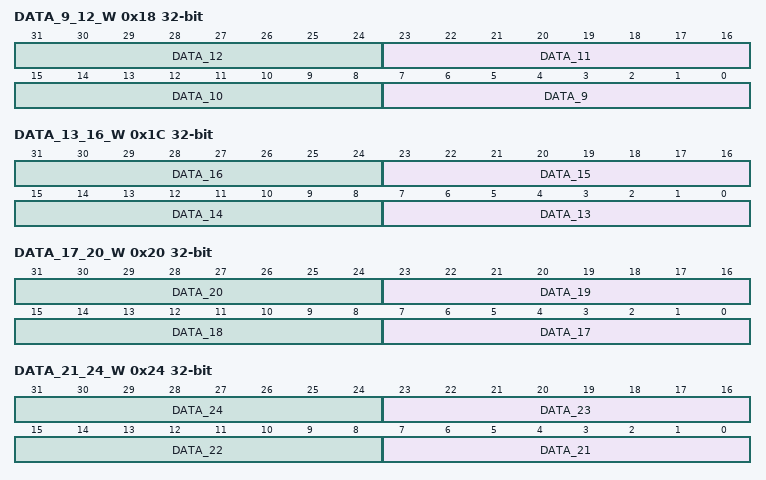
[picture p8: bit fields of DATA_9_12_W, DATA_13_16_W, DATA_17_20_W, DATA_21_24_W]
0x18 DATA_9_12_W
  [8n-65:8n-72] DATA_{n} (n=9..12) — Data byte {n} of CAN Frame.
0x1C DATA_13_16_W
  [8n-97:8n-104] DATA_{n} (n=13..16) — Data byte {n} of CAN Frame.
0x20 DATA_17_20_W
  [8n-129:8n-136] DATA_{n} (n=17..20) — Data byte {n} of CAN Frame.
0x24 DATA_21_24_W
  [8n-161:8n-168] DATA_{n} (n=21..24) — Data byte {n} of CAN Frame.
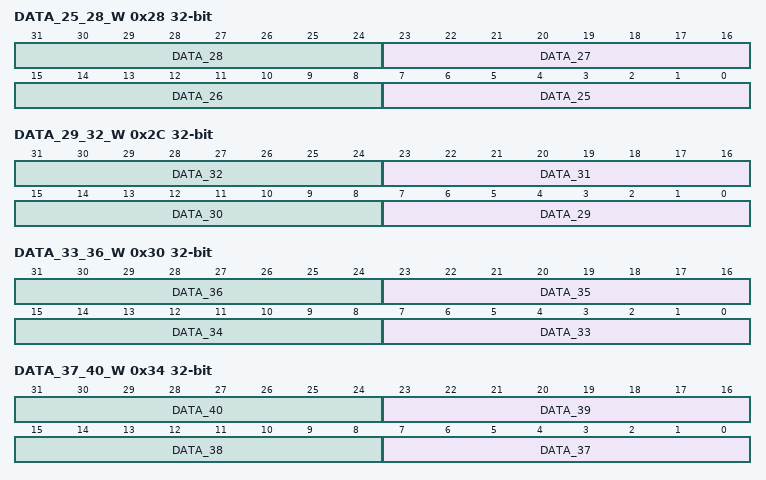
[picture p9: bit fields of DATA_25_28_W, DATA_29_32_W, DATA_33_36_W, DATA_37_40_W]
0x28 DATA_25_28_W
  [8n-193:8n-200] DATA_{n} (n=25..28) — Data byte {n} of CAN Frame.
0x2C DATA_29_32_W
  [8n-225:8n-232] DATA_{n} (n=29..32) — Data byte {n} of CAN Frame.
0x30 DATA_33_36_W
  [8n-257:8n-264] DATA_{n} (n=33..36) — Data byte {n} of CAN Frame.
0x34 DATA_37_40_W
  [8n-289:8n-296] DATA_{n} (n=37..40) — Data byte {n} of CAN Frame.
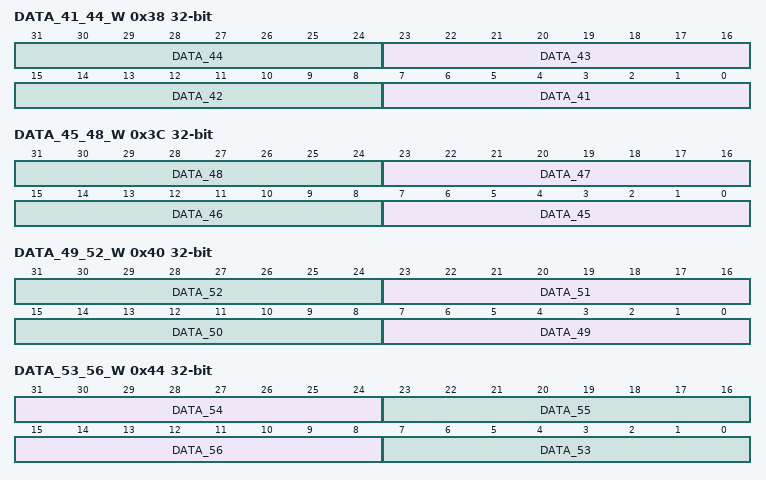
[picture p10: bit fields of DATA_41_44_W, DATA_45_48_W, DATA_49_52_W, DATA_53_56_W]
0x38 DATA_41_44_W
  [8n-321:8n-328] DATA_{n} (n=41..44) — Data byte {n} of CAN Frame.
0x3C DATA_45_48_W
  [8n-353:8n-360] DATA_{n} (n=45..48) — Data byte {n} of CAN Frame.
0x40 DATA_49_52_W
  [8n-385:8n-392] DATA_{n} (n=49..52) — Data byte {n} of CAN Frame.
0x44 DATA_53_56_W
  [31:24] DATA_54 — Data byte 54 of CAN Frame.
  [23:16] DATA_55 — Data byte 55 of CAN Frame.
  [15:8] DATA_56 — Data byte 56 of CAN Frame.
  [7:0] DATA_53 — Data byte 53 of CAN Frame.
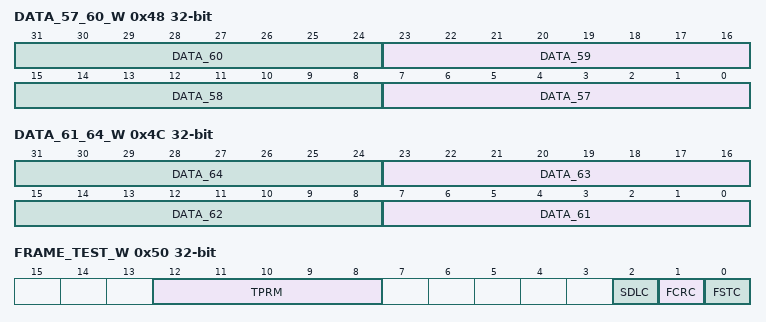
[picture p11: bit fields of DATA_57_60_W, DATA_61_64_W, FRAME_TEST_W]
0x48 DATA_57_60_W
  [8n-449:8n-456] DATA_{n} (n=57..60) — Data byte {n} of CAN Frame.
0x4C DATA_61_64_W
  [8n-481:8n-488] DATA_{n} (n=61..64) — Data byte {n} of CAN Frame.
0x50 FRAME_TEST_W
  [12:8] TPRM — Test Parameter
  [2] SDLC — Swap DLC in transmitted frame.
  [1] FCRC — Flip CRC field bit when this frame is transmitted. This field has effect only in transmitted frames.
  [0] FSTC — Flip Stuff count field bit when this frame is transmitted. This field has effect only in transmitted frames.
